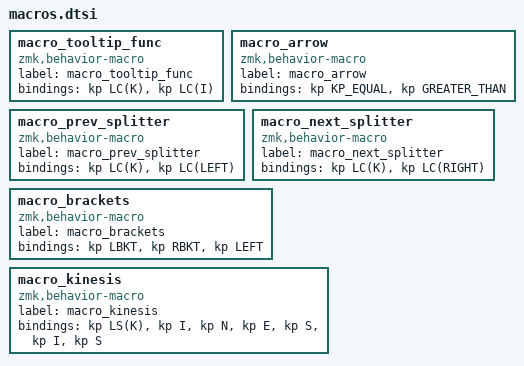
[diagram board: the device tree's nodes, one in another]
macro_tooltip_func: macro_tooltip_func{
compatible = "zmk,behavior-macro";
label = "macro_tooltip_func";
#binding-cells = <0>;
bindings = <&kp LC(K)>, <&kp LC(I)>;
};
macro_arrow: macro_arrow{
compatible = "zmk,behavior-macro";
label = "macro_arrow";
#binding-cells = <0>;
bindings = <&kp KP_EQUAL>, <&kp GREATER_THAN>;
};
macro_prev_splitter: macro_prev_splitter{
compatible = "zmk,behavior-macro";
label = "macro_prev_splitter";
#binding-cells = <0>;
bindings = <&kp LC(K)>, <&kp LC(LEFT)>;
};
macro_next_splitter: macro_next_splitter{
compatible = "zmk,behavior-macro";
label = "macro_next_splitter";
#binding-cells = <0>;
bindings = <&kp LC(K)>, <&kp LC(RIGHT)>;
};
macro_brackets: macro_brackets{
compatible = "zmk,behavior-macro";
label = "macro_brackets";
#binding-cells = <0>;
bindings = <&kp LBKT>, <&kp RBKT>, <&kp LEFT>;
};
macro_kinesis: macro_kinesis{
compatible = "zmk,behavior-macro";
label = "macro_kinesis";
#binding-cells = <0>;
bindings = <&kp LS(K)>, <&kp I>, <&kp N>, <&kp E>, <&kp S>, <&kp I>, <&kp S>;
};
